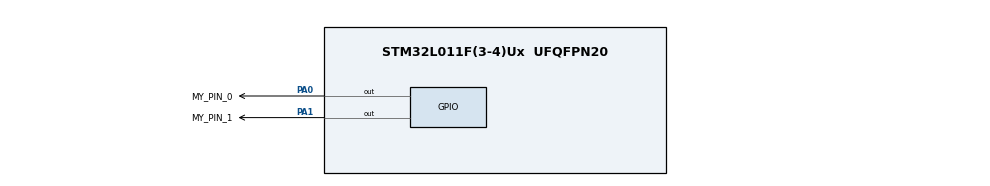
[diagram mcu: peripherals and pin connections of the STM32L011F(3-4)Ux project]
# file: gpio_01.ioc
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Mcu.Family=STM32L0
Mcu.Name=STM32L011F(3-4)Ux
Mcu.Package=UFQFPN20
PA0-CK_IN.GPIO_Label=MY_PIN_0
PA0-CK_IN.GPIO_PuPd=GPIO_PULLDOWN
PA0-CK_IN.Signal=GPIO_Output
PA1.GPIO_Label=MY_PIN_1
PA1.GPIO_PuPd=GPIO_PULLDOWN
PA1.GPIO_Speed=GPIO_SPEED_FREQ_LOW
PA1.Signal=GPIO_Output
ProjectManager.HeapSize=0x200
ProjectManager.StackSize=0x400
ProjectManager.TargetToolchain=Makefile
RCC.AHBFreq_Value=4194000
RCC.APB1Freq_Value=4194000
RCC.APB1TimFreq_Value=4194000
RCC.APB2Freq_Value=4194000
RCC.APB2TimFreq_Value=4194000
RCC.HCLKFreq_Value=4194000
RCC.HSE_VALUE=8000000
RCC.HSI16_VALUE=16000000
RCC.HSI_VALUE=16000000
RCC.LSE_VALUE=32768
RCC.MSIClockRange=RCC_MSIRANGE_6
RCC.MSI_VALUE=4194000
RCC.SYSCLKFreq_VALUE=4194000
RCC.VCOOutputFreq_Value=48000000
board=custom

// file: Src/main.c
/**
  ******************************************************************************
  * @file           : main.c
  * @brief          : Main program body
  ******************************************************************************
  ** This notice applies to any and all portions of this file
  * that are not between comment pairs USER CODE BEGIN and
  * USER CODE END. Other portions of this file, whether
  * inserted by the user or by software development tools
  * are owned by their respective copyright owners.
  *
  * COPYRIGHT(c) 2018 STMicroelectronics
  *
  * Redistribution and use in source and binary forms, with or without modification,
  * are permitted provided that the following conditions are met:
  *   1. Redistributions of source code must retain the above copyright notice,
  *      this list of conditions and the following disclaimer.
  *   2. Redistributions in binary form must reproduce the above copyright notice,
  *      this list of conditions and the following disclaimer in the documentation
  *      and/or other materials provided with the distribution.
  *   3. Neither the name of STMicroelectronics nor the names of its contributors
  *      may be used to endorse or promote products derived from this software
  *      without specific prior written permission.
  *
  * THIS SOFTWARE IS PROVIDED BY THE COPYRIGHT HOLDERS AND CONTRIBUTORS "AS IS"
  * AND ANY EXPRESS OR IMPLIED WARRANTIES, INCLUDING, BUT NOT LIMITED TO, THE
  * IMPLIED WARRANTIES OF MERCHANTABILITY AND FITNESS FOR A PARTICULAR PURPOSE ARE
  * DISCLAIMED. IN NO EVENT SHALL THE COPYRIGHT HOLDER OR CONTRIBUTORS BE LIABLE
  * FOR ANY DIRECT, INDIRECT, INCIDENTAL, SPECIAL, EXEMPLARY, OR CONSEQUENTIAL
  * DAMAGES (INCLUDING, BUT NOT LIMITED TO, PROCUREMENT OF SUBSTITUTE GOODS OR
  * SERVICES; LOSS OF USE, DATA, OR PROFITS; OR BUSINESS INTERRUPTION) HOWEVER
  * CAUSED AND ON ANY THEORY OF LIABILITY, WHETHER IN CONTRACT, STRICT LIABILITY,
  * OR TORT (INCLUDING NEGLIGENCE OR OTHERWISE) ARISING IN ANY WAY OUT OF THE USE
  * OF THIS SOFTWARE, EVEN IF ADVISED OF THE POSSIBILITY OF SUCH DAMAGE.
  *
  ******************************************************************************
  */
#include "main.h"
#include "gpio.h"

/* USER CODE BEGIN PV */
/* Private variables ---------------------------------------------------------*/

/* USER CODE END PV */

static void LL_Init(void);
void SystemClock_Config(void);

/* USER CODE BEGIN PFP */
/* Private function prototypes -----------------------------------------------*/

/* USER CODE END PFP */

int main(void)
{

  /* MCU Configuration----------------------------------------------------------*/

  /* Reset of all peripherals, Initializes the Flash interface and the Systick. */
  LL_Init();

  /* Configure the system clock */
  SystemClock_Config();

  /* Initialize all configured peripherals */
  MX_GPIO_Init();
  /* USER CODE BEGIN 2 */
//  MY_GPIO_Set (MY_PIN_0_GPIO_Port, MY_PIN_0_Pin);
//  MY_GPIO_Set (MY_PIN_1_GPIO_Port, MY_PIN_1_Pin);

  /* USER CODE END 2 */

  /* Infinite loop */
  /* USER CODE BEGIN WHILE */
  while (1)
  {
  MY_GPIO_Set (MY_PIN_0_GPIO_Port, MY_PIN_0_Pin);
  MY_GPIO_Set (MY_PIN_1_GPIO_Port, MY_PIN_1_Pin);
  MY_GPIO_Reset (MY_PIN_0_GPIO_Port,MY_PIN_0_Pin);
  MY_GPIO_Reset (MY_PIN_1_GPIO_Port, MY_PIN_1_Pin);

//  MY_GPIO_Toggle (MY_PIN_0_GPIO_Port, MY_PIN_0_Pin);
//  MY_GPIO_Toggle (MY_PIN_1_GPIO_Port, MY_PIN_1_Pin);
  /* USER CODE END WHILE */

  }

}
static void LL_Init(void)
{

  LL_APB2_GRP1_EnableClock(LL_APB2_GRP1_PERIPH_SYSCFG);
  LL_APB1_GRP1_EnableClock(LL_APB1_GRP1_PERIPH_PWR);

  /* System interrupt init*/
  /* SVC_IRQn interrupt configuration */
  NVIC_SetPriority(SVC_IRQn, 0);
  /* PendSV_IRQn interrupt configuration */
  NVIC_SetPriority(PendSV_IRQn, 0);
  /* SysTick_IRQn interrupt configuration */
  NVIC_SetPriority(SysTick_IRQn, 0);

}

void SystemClock_Config(void)
{

  LL_FLASH_SetLatency(LL_FLASH_LATENCY_0);

  if(LL_FLASH_GetLatency() != LL_FLASH_LATENCY_0)
  {
  Error_Handler();
  }
  LL_PWR_SetRegulVoltageScaling(LL_PWR_REGU_VOLTAGE_SCALE1);

  LL_RCC_MSI_Enable();

   /* Wait till MSI is ready */
  while(LL_RCC_MSI_IsReady() != 1)
  {

  }
  LL_RCC_MSI_SetRange(LL_RCC_MSIRANGE_6);

  LL_RCC_MSI_SetCalibTrimming(0);

  LL_RCC_SetAHBPrescaler(LL_RCC_SYSCLK_DIV_1);

  LL_RCC_SetAPB1Prescaler(LL_RCC_APB1_DIV_1);

  LL_RCC_SetAPB2Prescaler(LL_RCC_APB2_DIV_1);

  LL_RCC_SetSysClkSource(LL_RCC_SYS_CLKSOURCE_MSI);

   /* Wait till System clock is ready */
  while(LL_RCC_GetSysClkSource() != LL_RCC_SYS_CLKSOURCE_STATUS_MSI)
  {

  }
  LL_Init1msTick(4194000);

  LL_SYSTICK_SetClkSource(LL_SYSTICK_CLKSOURCE_HCLK);

  LL_SetSystemCoreClock(4194000);

  /* SysTick_IRQn interrupt configuration */
  NVIC_SetPriority(SysTick_IRQn, 0);
}

void _Error_Handler(char *file, int line)
{
  while(1)
  {
  }
}

/************************ (C) COPYRIGHT STMicroelectronics *****END OF FILE****/
